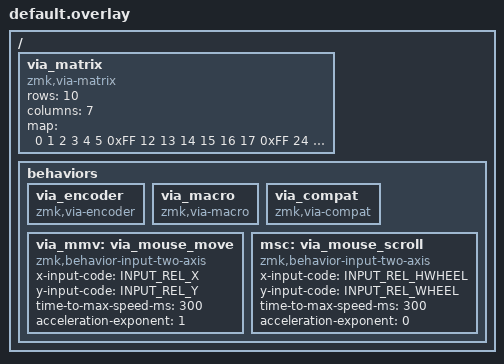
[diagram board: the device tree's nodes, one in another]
#include <zephyr/dt-bindings/input/input-event-codes.h>

/ {
    via_matrix: via_matrix {
        compatible = "zmk,via-matrix";
        rows = <10>;
        columns = <7>;
        map = <
            0 1 2 3 4 5 0xFF
            12 13 14 15 16 17 0xFF
            24 25 26 27 28 29 0xFF
            36 37 38 39 40 41 42
            50 51 52 53 54 0xFF 0xFF
            6 7 8 9 10 11 0xFF
            18 19 20 21 22 23 0xFF
            30 31 32 33 34 35 0xFF
            44 45 46 47 48 49 43
            55 56 57 58 59 0xFF 0xFF
        >;
    };

    behaviors {
        via_encoder: via_encoder {
            compatible = "zmk,via-encoder";
            #binding-cells = <1>;
            #sensor-binding-cells = <2>;
        };
        via_macro: via_macro {
            compatible = "zmk,via-macro";
            #binding-cells = <1>;
        };
        via_compat: via_compat {
            compatible = "zmk,via-compat";
            #binding-cells = <2>;
        };
        via_mmv: via_mouse_move {
            compatible = "zmk,behavior-input-two-axis";
            #binding-cells = <1>;
            x-input-code = <INPUT_REL_X>;
            y-input-code = <INPUT_REL_Y>;
            time-to-max-speed-ms = <300>;
            acceleration-exponent = <1>;
        };
        msc: via_mouse_scroll {
            compatible = "zmk,behavior-input-two-axis";
            #binding-cells = <1>;
            x-input-code = <INPUT_REL_HWHEEL>;
            y-input-code = <INPUT_REL_WHEEL>;
            time-to-max-speed-ms = <300>;
            acceleration-exponent = <0>;
        };
};
};
